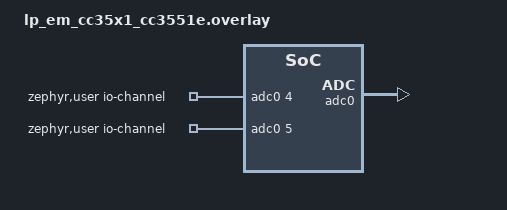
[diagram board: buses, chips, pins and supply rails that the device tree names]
/*
 * Copyright (c) 2026 Conclusive Engineering Sp. z o.o.
 *
 * SPDX-License-Identifier: Apache-2.0
 */

/ {
	zephyr,user {
		io-channels = <&adc0 4>, <&adc0 5>;
	};
};

&adc0 {
	status = "okay";
};
